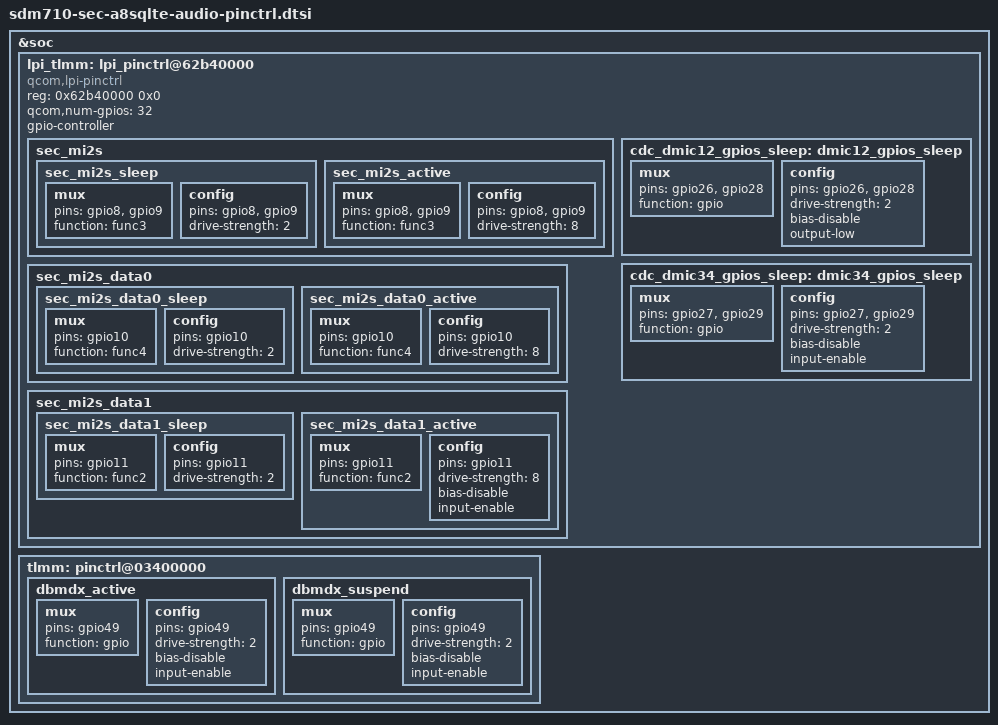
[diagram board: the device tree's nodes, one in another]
/* Copyright (c) 2016-2017, The Linux Foundation. All rights reserved.
 *
 * This program is free software; you can redistribute it and/or modify
 * it under the terms of the GNU General Public License version 2 and
 * only version 2 as published by the Free Software Foundation.
 *
 * This program is distributed in the hope that it will be useful,
 * but WITHOUT ANY WARRANTY; without even the implied warranty of
 * MERCHANTABILITY or FITNESS FOR A PARTICULAR PURPOSE.  See the
 * GNU General Public License for more details.
 */

&soc {
	lpi_tlmm: lpi_pinctrl@62b40000 {
		compatible = "qcom,lpi-pinctrl";
		reg = <0x62b40000 0x0>;
		qcom,num-gpios = <32>;
		gpio-controller;
		#gpio-cells = <2>;

		sec_mi2s {
			sec_mi2s_sleep: sec_mi2s_sleep {
				mux {
					pins = "gpio8", "gpio9";
					function = "func3";
				};
				config {
					pins = "gpio8", "gpio9";
					drive-strength = <2>; /* 2 mA */
				};
			};
			sec_mi2s_active: sec_mi2s_active {
				mux {
					pins = "gpio8", "gpio9";
					function = "func3";
				};
				config {
					pins = "gpio8", "gpio9";
					drive-strength = <8>; /* 8 mA */
					/* ouput-low; */
				};
			};
		};

		sec_mi2s_data0 {
			sec_mi2s_data0_sleep: sec_mi2s_data0_sleep {
				mux {
					pins = "gpio10";
					function = "func4";
				};
				config {
					pins = "gpio10";
					drive-strength = <2>; /* 2 mA */
				};
			};
			sec_mi2s_data0_active: sec_mi2s_data0_active {
				mux {
					pins = "gpio10";
					function = "func4";
				};
				config {
					pins = "gpio10";
					drive-strength = <8>; /* 8 mA */
					/* ouput-low; */
				};
			};
		};

		sec_mi2s_data1 {
			sec_mi2s_data1_sleep: sec_mi2s_data1_sleep {
				mux {
					pins = "gpio11";
					function = "func2";
				};
				config {
					pins = "gpio11";
					drive-strength = <2>; /* 2 mA */
				};
			};
			sec_mi2s_data1_active: sec_mi2s_data1_active {
				mux {
					pins = "gpio11";
					function = "func2";
				};
				config {
					pins = "gpio11";
					drive-strength = <8>; /* 8 mA */
					bias-disable;
					input-enable;
				};
			};
		};

		/delete-node/dmic12_gpios_sleep;
		cdc_dmic12_gpios_sleep: dmic12_gpios_sleep {
			mux {
				pins = "gpio26", "gpio28";
				function = "gpio";
			};

			config {
				pins = "gpio26", "gpio28";
				drive-strength = <2>;
				bias-disable;
				output-low;
			};
		};

		/delete-node/dmic34_gpios_sleep;
		cdc_dmic34_gpios_sleep: dmic34_gpios_sleep {
			mux {
				pins = "gpio27", "gpio29";
				function = "gpio";
			};

			config {
				pins = "gpio27", "gpio29";
				drive-strength = <2>;
				bias-disable;
				input-enable;
			};
		};
	};

	tlmm: pinctrl@03400000 {
		dbmdx_active: dbmdx_active {
			mux {
				pins = "gpio49";
				function = "gpio";
			};
			config {
				pins = "gpio49";
				drive-strength = <2>;
				bias-disable;
				input-enable;
			};
		};

		dbmdx_suspend: dbmdx_suspend {
			mux {
				pins = "gpio49";
				function = "gpio";
			};
			config {
				pins = "gpio49";
				drive-strength = <2>;
				bias-disable;
				input-enable;
			};
		};
	};
};
